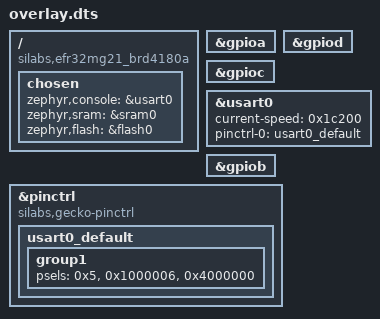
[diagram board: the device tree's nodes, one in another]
/ {
	compatible = "silabs,efr32mg21_brd4180a", "silabs,efr32mg21";
	chosen {
		zephyr,console = &usart0;
		zephyr,sram = &sram0;
		zephyr,flash = &flash0;
	};
};
&gpioa{
	status = "okay";
};
&gpiod{
	status = "okay";
};
&gpioc{
	status = "okay";
};
&usart0{
	status = "okay";
	current-speed = < 0x1c200 >;
	pinctrl-0 = < &usart0_default >;
	pinctrl-names = "default";
};
&gpiob{
	status = "okay";
};
&pinctrl{
	compatible = "silabs,gecko-pinctrl";
	usart0_default: usart0_default {
		group1 {
			psels = < 0x5 >, < 0x1000006 >, < 0x4000000 >;
		};
	};
};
